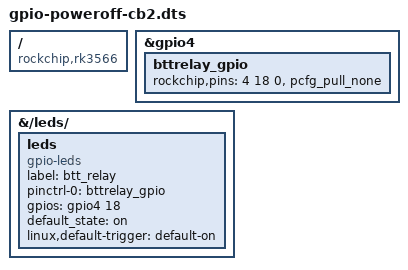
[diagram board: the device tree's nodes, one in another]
/dts-v1/;
/plugin/;

/ {

    compatible = "rockchip,rk3566";


    fragment@0 {
        target = <&gpio4>;
        __overlay__ {
                bttrelay_gpio: bttrelay_gpio {
                        rockchip,pins = <4 18 0 &pcfg_pull_none>; //gpio4_c2   8*('c'-'a') + 2 = 18
                };

            };
        };
    

    fragment@1 {
        target-path = "/leds/";
        __overlay__ {
                leds: leds {
                        compatible = "gpio-leds";
                        label = "btt_relay";
                        pinctrl-names = "default";
                        pinctrl-0 =<&bttrelay_gpio>;

                        gpios = <&gpio4 18 0>; //gpio4_c2
                        default_state="on";
                        linux,default-trigger = "default-on";
                };
        };
    };
};
